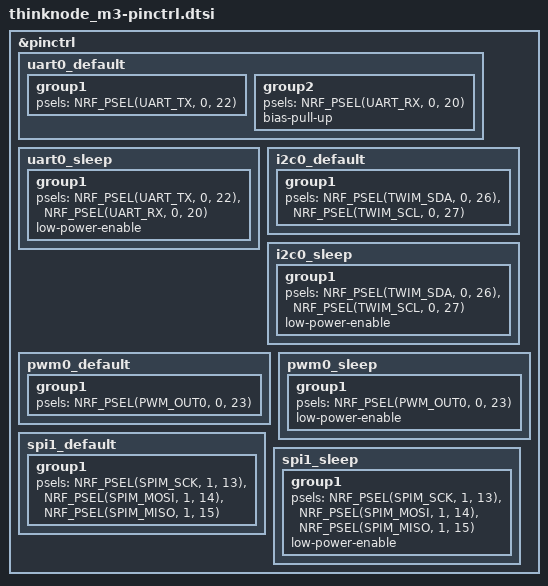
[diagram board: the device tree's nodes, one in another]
/*
 * Elecrow ThinkNode M3 - Pin Control
 * Copyright (c) 2025 ZephCore
 * SPDX-License-Identifier: MIT
 *
 * Pin assignments from Arduino variant.h and platformio.ini:
 * - SPI: SCK=P1.13, MOSI=P1.14, MISO=P1.15, NSS=P1.12 (for LR1110)
 * - I2C: SDA=P0.26, SCL=P0.27
 * - UART0: TX=P0.22 (PIN_GPS_RX→GPS), RX=P0.20 (PIN_GPS_TX←GPS) at 9600 baud
 * - LR1110: DIO1=P1.08, BUSY=P1.11, RESET=P1.10
 * - PWM: P0.23 (buzzer, from PIN_BUZZER=23 in platformio.ini)
 */

&pinctrl {
	/* GPS UART0 - 9600 baud
	 * Note: PIN_GPS_TX/RX naming is from GPS module's perspective in variant.h.
	 * nRF UART TX → P0.22 (PIN_GPS_RX), nRF UART RX ← P0.20 (PIN_GPS_TX). */
	uart0_default: uart0_default {
		group1 {
			psels = <NRF_PSEL(UART_TX, 0, 22)>;
		};
		group2 {
			psels = <NRF_PSEL(UART_RX, 0, 20)>;
			bias-pull-up;
		};
	};

	uart0_sleep: uart0_sleep {
		group1 {
			psels = <NRF_PSEL(UART_TX, 0, 22)>,
			        <NRF_PSEL(UART_RX, 0, 20)>;
			low-power-enable;
		};
	};

	/* I2C0 for on-board sensors */
	i2c0_default: i2c0_default {
		group1 {
			psels = <NRF_PSEL(TWIM_SDA, 0, 26)>,
			        <NRF_PSEL(TWIM_SCL, 0, 27)>;
		};
	};

	i2c0_sleep: i2c0_sleep {
		group1 {
			psels = <NRF_PSEL(TWIM_SDA, 0, 26)>,
			        <NRF_PSEL(TWIM_SCL, 0, 27)>;
			low-power-enable;
		};
	};

	/* PWM0 for buzzer on P0.23 (PIN_BUZZER=23 from platformio.ini) */
	pwm0_default: pwm0_default {
		group1 {
			psels = <NRF_PSEL(PWM_OUT0, 0, 23)>;
		};
	};

	pwm0_sleep: pwm0_sleep {
		group1 {
			psels = <NRF_PSEL(PWM_OUT0, 0, 23)>;
			low-power-enable;
		};
	};

	/* SPI1 for LR1110 - CS controlled manually (P1.12) */
	spi1_default: spi1_default {
		group1 {
			psels = <NRF_PSEL(SPIM_SCK, 1, 13)>,
			        <NRF_PSEL(SPIM_MOSI, 1, 14)>,
			        <NRF_PSEL(SPIM_MISO, 1, 15)>;
		};
	};

	spi1_sleep: spi1_sleep {
		group1 {
			psels = <NRF_PSEL(SPIM_SCK, 1, 13)>,
			        <NRF_PSEL(SPIM_MOSI, 1, 14)>,
			        <NRF_PSEL(SPIM_MISO, 1, 15)>;
			low-power-enable;
		};
	};
};
